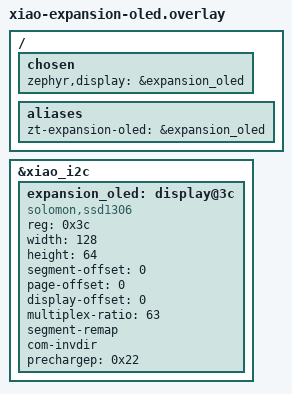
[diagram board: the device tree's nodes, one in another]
/*
 * SPDX-License-Identifier: Apache-2.0
 * OLED parameters from the pinned Zephyr seeed_xiao_expansion_board shield.
 * Copyright (c) 2024 Charles Dias <charlesdias.cd@outlook.com>
 */
/ {
    chosen { zephyr,display = &expansion_oled; };
    aliases { zt-expansion-oled = &expansion_oled; };
};

&xiao_i2c {
    status = "okay";
    expansion_oled: display@3c {
        compatible = "solomon,ssd1306";
        reg = <0x3c>;
        width = <128>;
        height = <64>;
        segment-offset = <0>;
        page-offset = <0>;
        display-offset = <0>;
        multiplex-ratio = <63>;
        segment-remap;
        com-invdir;
        prechargep = <0x22>;
    };
};
